# EFR32BG21A020F1024IM32 register map
Vendor: Silicon Labs; Series: EFR32; File version: B
Registers are 32-bit, read-write, reset 0x0 unless marked. A register's access mark holds for its fields unless they carry their own. Offsets are from the block's base; [hi:lo] are bit positions; {n}, {i} and the like mark numbered series; 'fields as' and 'values as' point back to an identical list.

## RAC_S — RAC_S Registers
Base 0xA8020000
Same registers: RAC_NS 0xB8020000
0x00 IPVERSION ro
0x04 EN
  [0] EN — Enable peripheral clock to this module
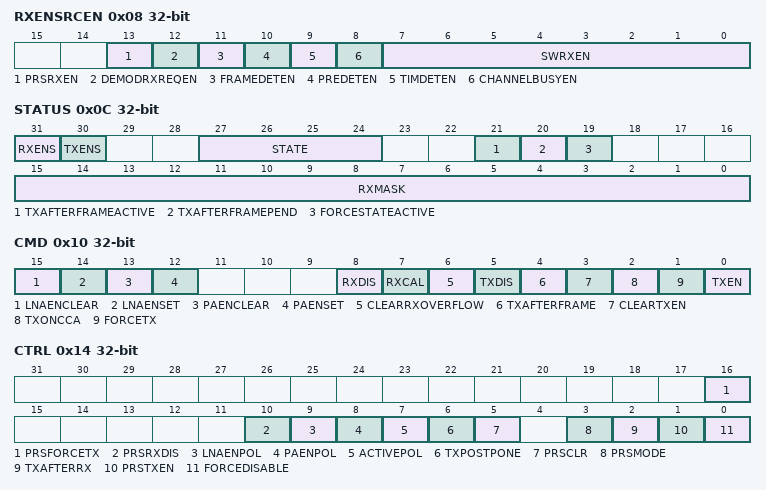
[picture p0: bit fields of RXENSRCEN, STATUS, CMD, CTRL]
0x08 RXENSRCEN
  [13] PRSRXEN — PRS RX Enable
  [12] DEMODRXREQEN — DEMOD RX Request Enable
  [11] FRAMEDETEN — Frame Detected Enable
  [10] PREDETEN — Preamble Detected Enable
  [9] TIMDETEN — Timing Detected Enable
  [8] CHANNELBUSYEN — Channel Busy Enable
  [7:0] SWRXEN — SW RX Enable
0x0C STATUS ro
  [31] RXENS — RXEN Status
    0=RXEN is not set; 1=RXEN is set
  [30] TXENS — TXEN Status
    0=TXEN is not set; 1=TXEN is set
  [27:24] STATE — Radio State
    0=OFF (Radio is off); 1=RXWARM (Radio is enabling receiver); 2=RXSEARCH (Radio is listening for incoming frames); 3=RXFRAME (Radio is receiving a frame); 4=RXPD (Radio is powering down receiver and going to OFF state); 5=RX2RX (Radio remains in receive mode after frame reception is completed); 6=RXOVERFLOW (Received data was lost due to full receive buffer); 7=RX2TX (Radio is disabling receiver and enabling transmitter); 8=TXWARM (Radio is enabling transmitter); 9=TX (Radio is transmitting data); 10=TXPD (Radio is powering down transmitter and going to OFF state); 11=TX2RX (Radio is disabling transmitter and enabling reception); 12=TX2TX (Radio is preparing for a transmission after the previous transmission was ended); 13=SHUTDOWN (Radio is powering down receiver and going to OFF state)
  [21] TXAFTERFRAMEACTIVE
    0=The currently ongoing TX was not initiated by a TXAFTERFRAME command; 1=The currently ongoing TX was initiated by a TXAFTERFRAME command
  [20] TXAFTERFRAMEPEND — TX After Frame Pending
    0=A transmit after frame operation is currently not pending; 1=A transmit after frame operation is currently pending
  [19] FORCESTATEACTIVE — FSM state force active
    0=No special state transition is currently in progress; 1=A forced state transition is currently in progress
  [15:0] RXMASK — Receive Enable Mask
0x10 CMD wo
  [15] LNAENCLEAR
  [14] LNAENSET
  [13] PAENCLEAR
  [12] PAENSET
  [8] RXDIS — RX Disable
  [7] RXCAL — Start an RX Calibration
  [6] CLEARRXOVERFLOW
  [5] TXDIS — TX Disable
  [4] TXAFTERFRAME
  [3] CLEARTXEN — Clear TX Enable
  [2] TXONCCA — Transmit On CCA
  [1] FORCETX — Force TX Command
  [0] TXEN — Transmitter Enable
0x14 CTRL
  [16] PRSFORCETX — PRS Force RX
    0=PRS will not force TX; 1=The channel selected by PRSFORCETXSEL will generate a force TX pulse
  [10] PRSRXDIS — PRS RX Disable
    0=PRS will not disable RX; 1=The channel selected by PRSRXDISSEL will generate a disable RX pulse
  [9] LNAENPOL — LNAEN signal polarity
    0=Active low; 1=Active high
  [8] PAENPOL — PAEN signal polarity
    0=Active low; 1=Active high
  [7] ACTIVEPOL — ACTIVE signal polarity
    0=Active low; 1=Active high
  [6] TXPOSTPONE
    0=In the TX state transmit data is output; 1=In the TX state an unmodulated carrier is output until this bit is cleared
  [5] PRSCLR — PRS RXEN Clear
    0=RXSEARCH (The PRS RXEN signal is cleared when the RSM state enters RXSEARCH); 1=PRSCH (The Selected PRS channel in PRSCLRSEL is used as a disable pulse)
  [3] PRSMODE — PRS RXEN Mode
    0=DIRECT (The PRS signal is used directly); 1=PULSE (The PRS signal is used as an RX enable pulse)
  [2] TXAFTERRX
    0=TX will not be started automatically; 1=A transition to TX is automatically started when a received frame is accepted by the FRC
  [1] PRSTXEN — PRS TX Enable
  [0] FORCEDISABLE — Force Radio Disable
0x18 FORCESTATE
  [3:0] FORCESTATE — Force RAC state transition
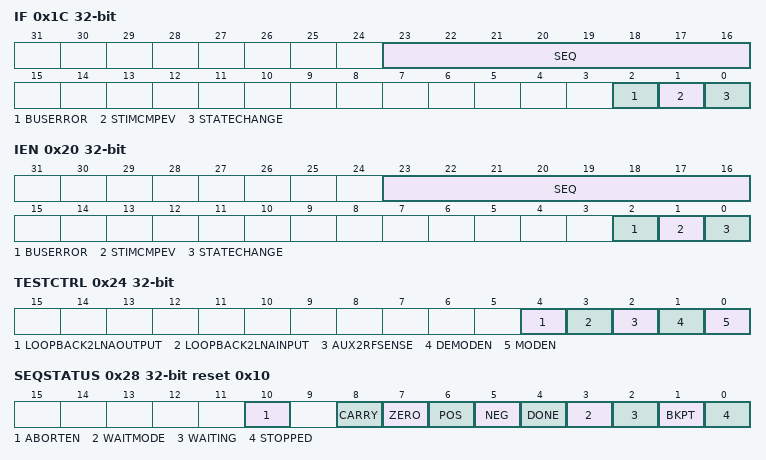
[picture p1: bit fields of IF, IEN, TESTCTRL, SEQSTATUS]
0x1C IF
  [23:16] SEQ — Sequencer Interrupt Flags
  [2] BUSERROR
  [1] STIMCMPEV — STIMER Compare Event
  [0] STATECHANGE — Radio State Change
0x20 IEN
  [23:16] SEQ — Sequencer Flags Interrupt Enable
  [2] BUSERROR — Bus Error Interrupt Enable
  [1] STIMCMPEV — STIMER Compare Event Interrupt Enable
  [0] STATECHANGE — Radio State Change Interrupt Enable
0x24 TESTCTRL
  [4] LOOPBACK2LNAOUTPUT — Enable RF loopback
  [3] LOOPBACK2LNAINPUT — Enable RF loopback
  [2] AUX2RFSENSE — Enable auxiliary synthesizer output
    0=The auxiliary synthesizer is not connected to the RFSENSE input; 1=The auxiliary synthesizer is connected to the RFSENSE input
  [1] DEMODEN — Demodulator enable
  [0] MODEN — Modulator enable
0x28 SEQSTATUS ro reset 0x10
  [10] ABORTEN — Sequencer Program Execution Abort Enable
    0=Sequencer Program Execution can not be aborted; 1=Sequencer Program Execution can be aborted
  [8] CARRY — Carry Flag
  [7] ZERO — Zero Flag
  [6] POS — Positive Flag
  [5] NEG — Negative Flag
  [4] DONE — Sequencer Done Signal
  [3] WAITMODE — Sequencer Waiting Mode
    0=ANY (Sequencer is waiting for any of the events indicated SEQ_WAITMASK.); 1=ALL (Sequencer is waiting for all the events indicated SEQ_WAITMASK.)
  [2] WAITING — Sequencer Waiting
  [1] BKPT — Breakpoint Enabled
  [0] STOPPED — Sequencer Stopped
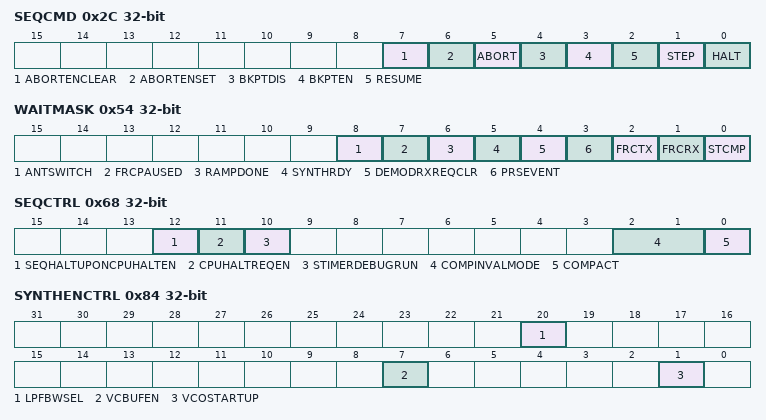
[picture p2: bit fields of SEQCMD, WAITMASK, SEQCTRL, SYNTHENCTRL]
0x2C SEQCMD wo
  [7] ABORTENCLEAR — Clear Sequencer Abort Enable
  [6] ABORTENSET — Set Sequencer Abort Enable
  [5] ABORT — Sequencer Execution Abort
  [4] BKPTDIS — Breakpoint Disable
  [3] BKPTEN — Breakpoint Enable
  [2] RESUME — Sequencer Resume
  [1] STEP — Sequencer Step
  [0] HALT — Sequencer Halt
0x30 BREAKPOINT
  [31:0] BKPADDR — Sequencer Breakpoint Address
{0x34+4i} R{i} (i=0..7)
  [31:0] R{i} — Sequencer Register {i}
0x54 WAITMASK ro
  [8] ANTSWITCH — Active antenna has switched
  [7] FRCPAUSED
  [6] RAMPDONE
  [5] SYNTHRDY — SYNTH Ready
  [4] DEMODRXREQCLR — Demodulator RX Request Clear
  [3] PRSEVENT
  [2] FRCTX — FRC TXWord
  [1] FRCRX — FRC RXWord
  [0] STCMP — STIMER Compare Event
0x58 WAITSNSH ro
  [9:0] WAITSNSH — Wait Event Snapshot
0x5C STIMER ro
  [15:0] STIMER
0x60 STIMERCOMP
  [15:0] STIMERCOMP — STIMER Compare Register
0x64 VECTADDR
  [31:0] VECTADDR — Vector Table Address
0x68 SEQCTRL
  [12] SEQHALTUPONCPUHALTEN — Sequencer Halt Upon CPU Halt Enable
    0=Sequencer is not halted when the main CPU is halted; 1=Sequencer is halted when the main CPU is halted
  [11] CPUHALTREQEN — CPU Halt Request Enable
    0=Main CPU is not halted when the Sequencer is halted; 1=Main CPU is halted when the Sequencer is halted
  [10] STIMERDEBUGRUN
    0=STIMER is not running when the Sequencer is halted; 1=STIMER is running when the Sequencer is halted
  [2:1] COMPINVALMODE — STIMER Comp Invalid Mode
    0=NEVER (STIMERCOMP is always valid); 1=STATECHANGE (STIMERCOMP is invalidated when the RSM changes state); 2=COMPEVENT (STIMERCOMP is invalidated when an STIMER compare event occurs); 3=STATECOMP (STIMERCOMP is invalidated both when the RSM changes state and when a compare event occurs)
  [0] COMPACT — STIMER Compare Action
    0=WRAP (STIMER wraps when reaching STIMERCOMP); 1=CONTINUE (STIMER continues when reaching STIMERCOMP)
0x6C PRESC reset 0x7
  [6:0] STIMER — STIMER Prescaler
{0x70+4i} SR{i} (i=0..3)
  [31:0] SR{i} — Sequencer Storage Register {i}
0x84 SYNTHENCTRL
  [20] LPFBWSEL — LPF bandwidth register selection
    0=LPFBWRX (Select LPFBWRX); 1=LPFBWTX (Select LPFBWTX)
  [7] VCBUFEN — SYLPFVCBUFEN
    0=Disabled; 1=Enabled
  [1] VCOSTARTUP — SYVCOFASTSTARTUP
    0=fast_start_up_0; 1=fast_start_up_1
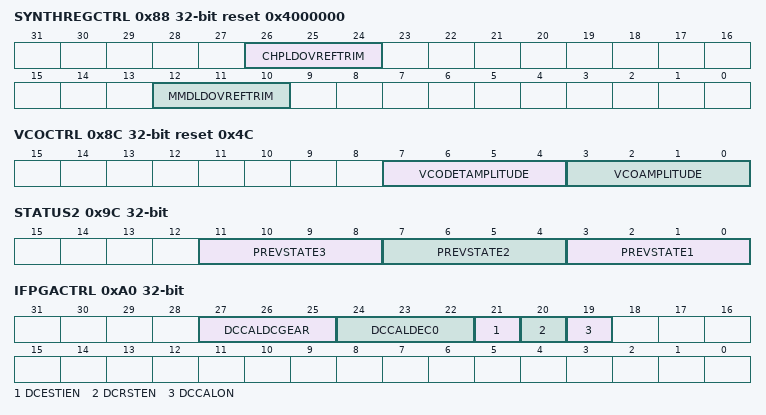
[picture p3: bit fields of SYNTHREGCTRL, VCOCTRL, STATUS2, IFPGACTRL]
0x88 SYNTHREGCTRL reset 0x4000000
  [26:24] CHPLDOVREFTRIM — SYTRIMCHPREGVREF
    0=vref0p6000; 1=vref0p6125; 2=vref0p6250; 3=vref0p6375; 4=vref0p6500; 5=vref0p6625; 6=vref0p6750; 7=vref0p6875
  [12:10] MMDLDOVREFTRIM — SYTRIMMMDREGVREF
    values as CHPLDOVREFTRIM
0x8C VCOCTRL reset 0x4C
  [7:4] VCODETAMPLITUDE — SYVCOAMPLPKD
  [3:0] VCOAMPLITUDE — SYVCOAMPLOPEN
0x94 SYNTHCTRL
  [10] MMDPOWERBALANCEDISABLE — SYMMDPOWERBALANCEENB
    0=EnablePowerbleed; 1=DisablePowerBleed
0x9C STATUS2 ro
  [all] fields
    values as STATUS.STATE
  [11:8] PREVSTATE3 — Previous Radio State 3
  [7:4] PREVSTATE2 — Previous Radio State 2
  [3:0] PREVSTATE1 — Previous Radio State
0xA0 IFPGACTRL
  [27:25] DCCALDCGEAR — DC COMP GEAR Value for DCCAL
  [24:22] DCCALDEC0 — DEC0 Value for DCCAL
    0=DF3 (Decimation Factor 0 = 3. Cutoff 0.050 * f<subscript>HFXO</subscript>.); 1=DF4WIDE (Decimation Factor 0 = 4. Cutoff 0.069 * f<subscript>HFXO</subscript>.); 2=DF4NARROW (Decimation Factor 0 = 4. Cutoff 0.037 * f<subscript>HFXO</subscript>.); 3=DF8WIDE (Decimation Factor 0 = 8. Cutoff 0.012 * f<subscript>HFXO</subscript>.); 4=DF8NARROW (Decimation Factor 0 = 8. Cutoff 0.005 * f<subscript>HFXO</subscript>.)
  [21] DCESTIEN — DCESTIEN Override for RAC
    0=DISABLE (DCESTI Disabled in MODEM); 1=ENABLE (DCESTI Enabled in MODEM)
  [20] DCRSTEN — DC Compensation Filter Reset Enable
    0=DISABLE (DC Comp out of Reset); 1=ENABLE (DC Comp in Reset)
  [19] DCCALON — Enable/Disable DCCAL in DEMOD
    0=DISABLE (DC ESTI DISABLED); 1=ENABLE (DC ESTI ENABLED)
0xA4 PAENCTRL
  [8] PARAMP — PA output level ramping
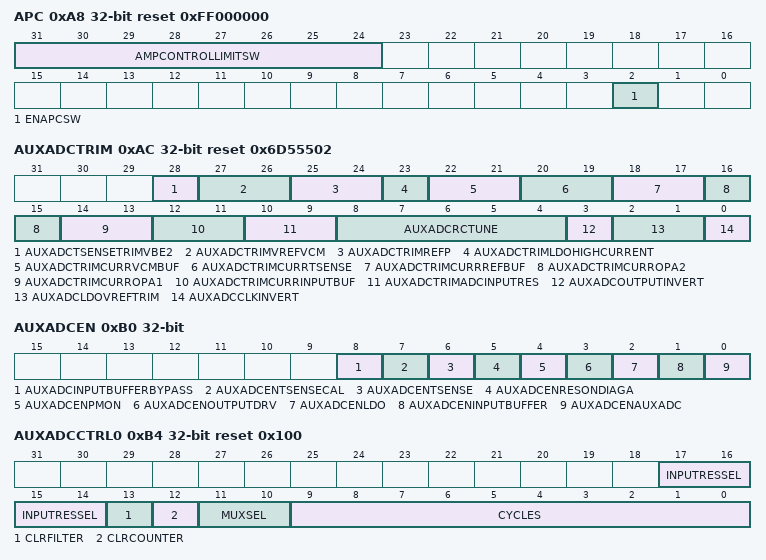
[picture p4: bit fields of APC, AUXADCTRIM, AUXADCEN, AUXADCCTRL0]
0xA8 APC reset 0xFF000000
  [31:24] AMPCONTROLLIMITSW — software amp_control top limit
  [2] ENAPCSW — software control bit for apc
    0=DISABLE; 1=ENABLE
0xAC AUXADCTRIM reset 0x6D55502
  [28] AUXADCTSENSETRIMVBE2
    0=VBE_16uA; 1=VBE_32uA
  [27:26] AUXADCTRIMVREFVCM
    0=Trim0p6; 1=Trim0p65; 2=Trim0p7; 3=Trim0p75
  [25:24] AUXADCTRIMREFP
    0=REF1p05; 1=REF1p16; 2=REF1p2; 3=REF1p25
  [23] AUXADCTRIMLDOHIGHCURRENT
    0=LowCurrentMode; 1=HighCurrentMode
  [22:21] AUXADCTRIMCURRVCMBUF
    0=Typ_minus_40pct; 1=Typ_minus_20pct; 2=Typ; 3=Typ_plus_20pct
  [20:19] AUXADCTRIMCURRTSENSE
    values as AUXADCTRIMCURRVCMBUF
  [18:17] AUXADCTRIMCURRREFBUF
    values as AUXADCTRIMCURRVCMBUF
  [16:15] AUXADCTRIMCURROPA2
    values as AUXADCTRIMCURRVCMBUF
  [14:13] AUXADCTRIMCURROPA1
    values as AUXADCTRIMCURRVCMBUF
  [12:11] AUXADCTRIMCURRINPUTBUF
    values as AUXADCTRIMCURRVCMBUF
  [10:9] AUXADCTRIMADCINPUTRES
    0=RES200k; 1=RES250k; 2=RES300k; 3=RES350k
  [8:4] AUXADCRCTUNE
  [3] AUXADCOUTPUTINVERT
    0=Disabled; 1=Enabled
  [2:1] AUXADCLDOVREFTRIM
    0=TRIM1p27; 1=TRIM1p3; 2=TRIM1p35; 3=TRIM1p4
  [0] AUXADCCLKINVERT
    0=Disable_Invert; 1=Enable_Invert
0xB0 AUXADCEN
  [8] AUXADCINPUTBUFFERBYPASS
    0=Not_Bypassed; 1=Bypassed
  [7] AUXADCENTSENSECAL
    0=Disabled; 1=Enabled
  [6] AUXADCENTSENSE
    0=Disabled; 1=Enabled
  [5] AUXADCENRESONDIAGA
    0=Disabled; 1=Enabled
  [4] AUXADCENPMON
    0=Disabled; 1=Enabled
  [3] AUXADCENOUTPUTDRV
    0=Disabled; 1=Enabled
  [2] AUXADCENLDO
    0=Disabled; 1=Enabled
  [1] AUXADCENINPUTBUFFER
    0=Disabled; 1=Enabled
  [0] AUXADCENAUXADC
    0=Disabled; 1=Enabled
0xB4 AUXADCCTRL0 reset 0x100
  [17:14] INPUTRESSEL — Select input resource
  [13] CLRFILTER — Clear accumulators
  [12] CLRCOUNTER — Clear counter
  [11:10] MUXSEL — Select accumulator
  [9:0] CYCLES — Cycle number to run
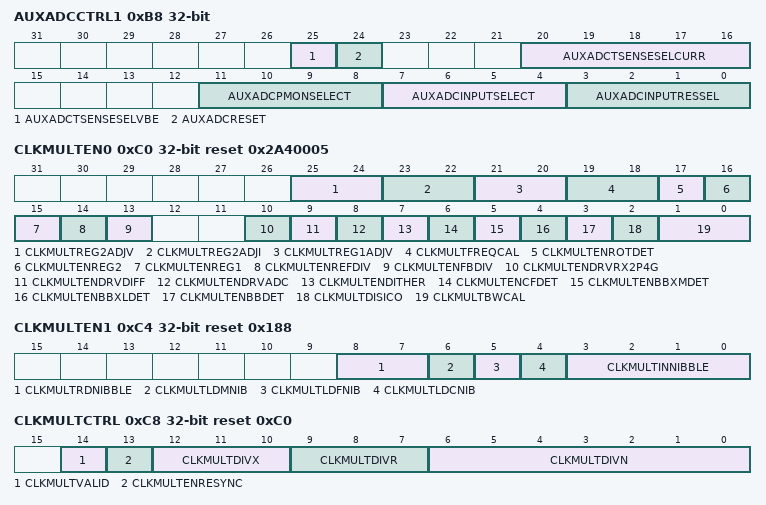
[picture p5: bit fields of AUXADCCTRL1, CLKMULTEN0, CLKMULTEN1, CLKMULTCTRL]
0xB8 AUXADCCTRL1
  [25] AUXADCTSENSESELVBE
    0=VBE1; 1=VBE2
  [24] AUXADCRESET
    0=Reset_Enabled; 1=Reset_Disabled
  [20:16] AUXADCTSENSESELCURR
  [11:8] AUXADCPMONSELECT
  [7:4] AUXADCINPUTSELECT
    {v}=SEL{v} (v=0..9)
  [3:0] AUXADCINPUTRESSEL
    0=RES640kOhm; 1=RES320kOhm; 2=RES160kOhm; 3=RES80kOhm; 4=RES40kOhm; 5=RES20kOhm; 6=RES10kOhm; 7=RES5kOhm; 8=RES2p5kOhm; 9=RES1p25kOhm; 10=RES0p6kOhm; 11=RES_switch
0xBC AUXADCOUT ro
  [27:0] AUXADCOUT — AUXADC output
0xC0 CLKMULTEN0 reset 0x2A40005
  [25:24] CLKMULTREG2ADJV
    0=v1p03; 1=v1p09; 2=v1p10; 3=v1p16
  [23:22] CLKMULTREG2ADJI
    0=I_200uA; 1=I_480uA; 2=I_760uA; 3=I_1040uA
  [21:20] CLKMULTREG1ADJV
    0=v1p28; 1=v1p32; 2=v1p33; 3=v1p38
  [19:18] CLKMULTFREQCAL
    0=pedes_14uA; 1=pedes_22uA; 2=pedes_30uA; 3=pedes_38uA
  [17] CLKMULTENROTDET
    0=disable; 1=enable
  [16] CLKMULTENREG2
    0=disable; 1=enable
  [15] CLKMULTENREG1
    0=disable; 1=enable
  [14] CLKMULTENREFDIV
    0=disable; 1=enable
  [13] CLKMULTENFBDIV
    0=disable; 1=enable
  [10] CLKMULTENDRVRX2P4G
    0=disable; 1=enable
  [9] CLKMULTENDRVDIFF
    0=Single_ended; 1=Differential
  [8] CLKMULTENDRVADC
    0=disable; 1=enable
  [7] CLKMULTENDITHER
    0=disable; 1=enable
  [6] CLKMULTENCFDET
    0=disable; 1=enable
  [5] CLKMULTENBBXMDET
    0=disable; 1=enable
  [4] CLKMULTENBBXLDET
    0=disable; 1=enable
  [3] CLKMULTENBBDET
    0=disable; 1=enable
  [2] CLKMULTDISICO
    0=enable; 1=disable
  [1:0] CLKMULTBWCAL
    {v}=bw_{v+1}lsb (v=0..3)
0xC4 CLKMULTEN1 reset 0x188
  [8:7] CLKMULTRDNIBBLE
    0=quarter_nibble; 1=fine_nibble; 2=moderate_nibble; 3=coarse_nibble
  [6] CLKMULTLDMNIB
    0=disable; 1=enable
  [5] CLKMULTLDFNIB
    0=disable; 1=enable
  [4] CLKMULTLDCNIB
    0=disable; 1=enable
  [3:0] CLKMULTINNIBBLE
0xC8 CLKMULTCTRL reset 0xC0
  [14] CLKMULTVALID
    0=invalid; 1=valid
  [13] CLKMULTENRESYNC
    0=disable_sync; 1=enable_sync
  [12:10] CLKMULTDIVX
    0=div_1; 1=div_2; 2=div_4; 3=div_6; 4=div_8; 5=div10; 6=div12; 7=div14
  [9:7] CLKMULTDIVR
  [6:0] CLKMULTDIVN
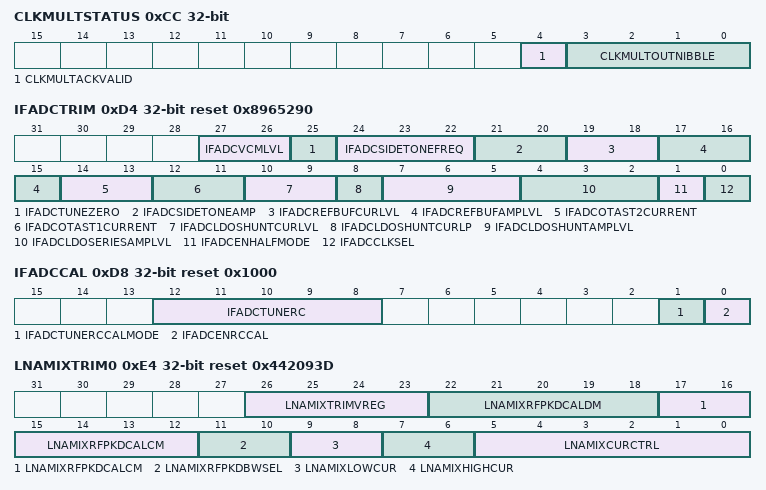
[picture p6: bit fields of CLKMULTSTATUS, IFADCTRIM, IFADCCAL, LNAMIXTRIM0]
0xCC CLKMULTSTATUS ro
  [4] CLKMULTACKVALID
    0=invalid; 1=valid
  [3:0] CLKMULTOUTNIBBLE
0xD4 IFADCTRIM reset 0x8965290
  [27:26] IFADCVCMLVL
    0=ratio_0p48; 1=ratio_0p49; 2=ratio_0p5; 3=ratio_0p52
  [25] IFADCTUNEZERO
    0=nominal_zero; 1=half_freq_zero
  [24:22] IFADCSIDETONEFREQ
    0=na0; 1=div_128; 2=div_64; 3=div_32; 4=div_16; 5=div_8; 6=div_4; 7=na7
  [21:20] IFADCSIDETONEAMP
    0=diff_pk_10mV; 1=diff_pk_20mV; 2=diff_pk_50mV; 3=diff_pk_100mV
  [19:18] IFADCREFBUFCURLVL
    0=current_65uA; 1=current_75uA; 2=current_85uA; 3=current_95uA
  [17:15] IFADCREFBUFAMPLVL
    0=v0p88; 1=v0p91; 2=v0p94; 3=v0p97; 4=v1p00; 5=v1p03; 6=v1p06; 7=v1p09
  [14:13] IFADCOTAST2CURRENT
    0=negative_20p; 1=negative_11p; 2=nominal; 3=positive_15p
  [12:11] IFADCOTAST1CURRENT
    0=negative_20p; 1=negative_11p; 2=nominal; 3=positive_15p
  [10:9] IFADCLDOSHUNTCURLVL
    0=current_180uA; 1=current_190uA; 2=current_200uA; 3=current_210uA
  [8] IFADCLDOSHUNTCURLP
    0=low_power_disabled; 1=low_power_enabled
  [7:5] IFADCLDOSHUNTAMPLVL
    0=v1p20; 1=v1p24; 2=v1p28; 3=v1p32; 4=v1p35; 5=v1p39; 6=v1p42; 7=v1p46
  [4:2] IFADCLDOSERIESAMPLVL
    values as IFADCLDOSHUNTAMPLVL
  [1] IFADCENHALFMODE
    0=full_speed_mode; 1=half_speed_mode
  [0] IFADCCLKSEL
    0=clk_2p4g; 1=clk_subg
0xD8 IFADCCAL reset 0x1000
  [12:8] IFADCTUNERC
  [1] IFADCTUNERCCALMODE
    0=SYmode; 1=ADCmode
  [0] IFADCENRCCAL
    0=rccal_disable; 1=rccal_enable
0xDC IFADCSTATUS ro
  [0] IFADCRCCALOUT
    0=lo; 1=hi
0xE4 LNAMIXTRIM0 reset 0x442093D
  [26:23] LNAMIXTRIMVREG
  [22:18] LNAMIXRFPKDCALDM
  [17:12] LNAMIXRFPKDCALCM
  [11:10] LNAMIXRFPKDBWSEL
  [9:8] LNAMIXLOWCUR
    0=current_nom; 2=current_80percent; 3=current_60percent
  [7:6] LNAMIXHIGHCUR
    0=current_470uA; 1=current_530uA; 3=current_590uA
  [5:0] LNAMIXCURCTRL
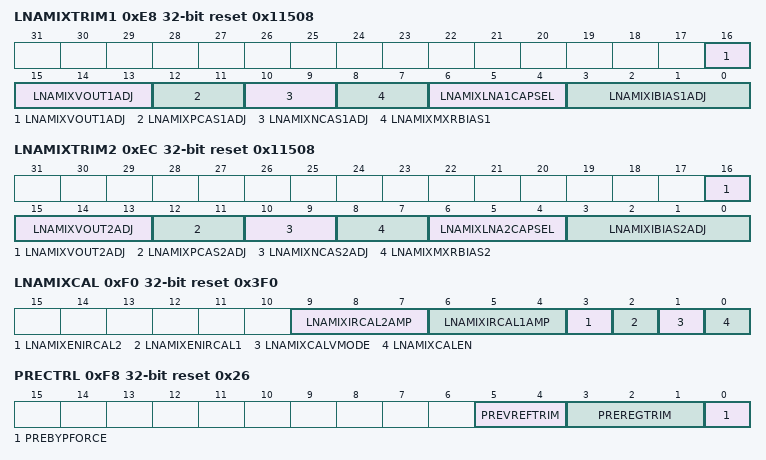
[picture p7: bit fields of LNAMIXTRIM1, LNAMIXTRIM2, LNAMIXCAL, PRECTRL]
0xE8 LNAMIXTRIM1 reset 0x11508
  [16:13] LNAMIXVOUT1ADJ
  [12:11] LNAMIXPCAS1ADJ
    0=pcas_250m; 2=pcas_300m; 3=pcas_350m
  [10:9] LNAMIXNCAS1ADJ
    0=ncas_1V; 2=ncas_950m; 3=ncas_900m
  [8:7] LNAMIXMXRBIAS1
    0=bias_1V; 2=bias_900m; 3=bias_800m
  [6:4] LNAMIXLNA1CAPSEL
  [3:0] LNAMIXIBIAS1ADJ
0xEC LNAMIXTRIM2 reset 0x11508
  [16:13] LNAMIXVOUT2ADJ
  [12:11] LNAMIXPCAS2ADJ
    0=pcas_250m; 2=pcas_300m; 3=pcas_350m
  [10:9] LNAMIXNCAS2ADJ
    0=ncas_1V; 2=ncas_950m; 3=ncas_900m
  [8:7] LNAMIXMXRBIAS2
    0=bias_1V; 2=bias_900m; 3=bias_800m
  [6:4] LNAMIXLNA2CAPSEL
  [3:0] LNAMIXIBIAS2ADJ
0xF0 LNAMIXCAL reset 0x3F0
  [9:7] LNAMIXIRCAL2AMP
  [6:4] LNAMIXIRCAL1AMP
  [3] LNAMIXENIRCAL2
    0=disable; 1=enable
  [2] LNAMIXENIRCAL1
    0=disable; 1=enable
  [1] LNAMIXCALVMODE
    0=current_mode; 1=voltage_mode
  [0] LNAMIXCALEN
    0=cal_disable; 1=cal_enable
0xF4 LNAMIXEN
  [0] LNAMIXENLDO
    0=disable; 1=enable
0xF8 PRECTRL reset 0x26
  [5:4] PREVREFTRIM
    0=v0p675; 1=v0p688; 2=v0p700; 3=v0p713
  [3:1] PREREGTRIM
    0=v1p61; 1=v1p68; 2=v1p74; 3=v1p80; 4=v1p86; 5=v1p91; 6=v1p96; 7=v2p00
  [0] PREBYPFORCE
    0=not_forced; 1=forced
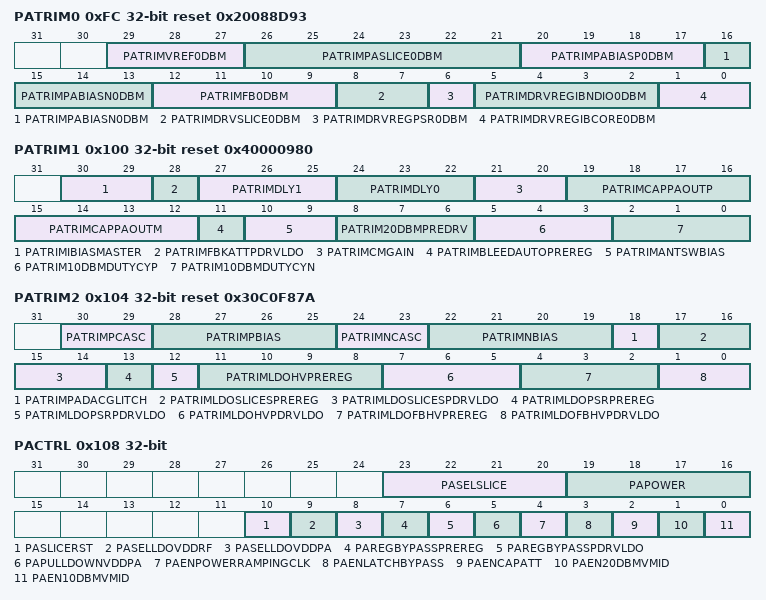
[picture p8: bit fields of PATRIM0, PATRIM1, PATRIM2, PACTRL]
0xFC PATRIM0 reset 0x20088D93
  [29:27] PATRIMVREF0DBM
    0=v_900m; 1=v_912p5m; 2=v_925m; 3=v_937p5m; 4=v_950m; 5=v_962p5m; 6=v_975m; 7=v_987p5m
  [26:21] PATRIMPASLICE0DBM
    0=on_slice_0; 63=on_slice_63
  [20:17] PATRIMPABIASP0DBM
    0=v_450m; 1=v_462p5m; 2=v_475m; 3=v_487p5m; 4=v_500m; 5=v_512p5m; 6=v_525m; 7=v_537p5m; 8=v_550m; 9=v_562p5m; 10=v_575m; 11=v_587p5m; 12=v_600m; 13=v_612p5m; 14=v_625m; 15=v_637p5m
  [16:13] PATRIMPABIASN0DBM
    values as PATRIMPABIASP0DBM
  [12:9] PATRIMFB0DBM
    0=vo_vi_0p475; 1=vo_vi_0p500; 2=vo_vi_0p525; 3=vo_vi_0p550; 4=vo_vi_0p575; 5=vo_vi_0p600; 6=vo_vi_0p625; 7=vo_vi_0p650; 8=vo_vi_0p675; 9=vo_vi_0p700; 10=vo_vi_0p725; 11=vo_vi_0p750; 12=vo_vi_0p775; 13=vo_vi_0p80; 14=vo_vi_0p825; 15=vo_vi_0p85
  [8:7] PATRIMDRVSLICE0DBM
    {v}=on_{v}_slice (v=0..3)
  [6] PATRIMDRVREGPSR0DBM
    0=disable; 1=enable
  [5:2] PATRIMDRVREGIBNDIO0DBM
    0=vreg_1p09; 1=vreg_1p13; 2=vreg_1p16; 3=vreg_1p20; 4=vreg_1p23; 5=vreg_1p25; 6=vreg_1p28; 7=vreg_1p31; 8=vreg_1p33; 9=vreg_1p36; {v}=NA_{v} (v=10..15)
  [1:0] PATRIMDRVREGIBCORE0DBM
    {v}=i_{v+4}u (v=0..3)
0x100 PATRIM1 reset 0x40000980
  [30:29] PATRIMIBIASMASTER
    0=Ibias_is_45u; 1=Ibias_is_47p5u; 2=Ibias_is_50u; 3=Ibias_is_52p5u
  [28] PATRIMFBKATTPDRVLDO
    0=less_bw; 1=more_bw
  [27:25] PATRIMDLY1
    0=tdly_0ps; 1=tdly_64ps; 2=tdly_65ps; 3=tdly_66ps; 4=tdly_68ps; 5=tdly_70ps; 6=tdly_75ps; 7=tdly_83ps
  [24:22] PATRIMDLY0
    values as PATRIMDLY1
  [21:20] PATRIMCMGAIN
  [19:16] PATRIMCAPPAOUTP
  [15:12] PATRIMCAPPAOUTM
  [11] PATRIMBLEEDAUTOPREREG
    0=not_automatic; 1=automatic
  [10:9] PATRIMANTSWBIAS
    0=vb_at_vdd; 1=vb_at_vdd_mp6v; 2=vb_at_vdd_m1p2v; 3=vb_at_vdd_m1p8v
  [8:6] PATRIM20DBMPREDRV
    0=trise_137ps; 1=trise_127ps; 2=trise_117ps; 3=trise_110ps; 4=trise_75ps; 5=trise_73ps; 6=trise_71ps; 7=trise_70ps
  [5:3] PATRIM10DBMDUTYCYP
    {v}=dn_{v}pct (v=0..6); 7=na
  [2:0] PATRIM10DBMDUTYCYN
    {v}=up_{v}pct (v=0..6); 7=na
0x104 PATRIM2 reset 0x30C0F87A
  [30:29] PATRIMPCASC
    0=pcbias_p50mv; 1=pcbias_default; 2=pcbias_m50mv; 3=pcbias_m100mv
  [28:25] PATRIMPBIAS
    0=vpbias_up104mv; 1=vpbias_up91mv; 2=vpbias_up78mv; 3=vpbias_up65mv; 4=vpbias_up52mv; 5=vpbias_up39mv; 6=vpbias_up26mv; 7=vpbias_up13mv; 8=vpbias_default; 9=vpbias_dn13mv; 10=vpbias_dn26mv; 11=vpbias_dn38mv; 12=vpbias_dn52mv; 13=vpbias_dn65mv; 14=vpbias_dn78mv; 15=vpbias_dn91mv
  [24:23] PATRIMNCASC
    0=ncbias_m50mv; 1=ncbias_default; 2=ncbias_p50mv; 3=ncbias_p100mv
  [22:19] PATRIMNBIAS
    0=vnbias_dn104mv; 1=vnbias_dn91mv; 2=vnbias_dn78mv; 3=vnbias_dn65mv; 4=vnbias_dn52mv; 5=vnbias_dn39mv; 6=vnbias_dn26mv; 7=vnbias_dn13mv; 8=vnbias_default; 9=vnbias_up13mv; 10=vnbias_up26mv; 11=vnbias_up39mv; 12=vnbias_up52mv; 13=vnbias_up65mv; 14=vnbias_up78mv; 15=vnbias_up91mv
  [18] PATRIMPADACGLITCH
    0=larger_glitch; 1=smaller_glitch
  [17:16] PATRIMLDOSLICESPREREG
    {v}=spare{v+1} (v=0..3)
  [15:14] PATRIMLDOSLICESPDRVLDO
    0=iload_7p5mA; 1=iload_15mA; 2=iload_22p5mA; 3=iload_30mA
  [13] PATRIMLDOPSRPREREG
    0=low_psr; 1=high_psr
  [12] PATRIMLDOPSRPDRVLDO
    0=low_psr; 1=high_psr
  [11:8] PATRIMLDOHVPREREG
    0=vref_0p651; 1=vref_0p663; 2=vref_0p676; 3=vref_0p688; 4=vref_0p701; 5=vref_0p713; 6=vref_0p726; 7=vref_0p738; 8=vref_0p751; 9=vref_0p763; 10=vref_0p776; 11=vref_0p788; 12=vref_0p801; 13=vref_0p813; 14=vref_0p826; 15=vref_0p838
  [7:5] PATRIMLDOHVPDRVLDO
    0=vref_0p675; 1=vref_0p700; 2=vref_0p725; 3=vref_0p750; 4=vref_0p775; 5=vref_0p800; 6=vref_0p825; 7=vref_0p850
  [4:2] PATRIMLDOFBHVPREREG
    0=vreg_1p678; 1=vreg_1p735; 2=vreg_1p801; 3=vreg_1p875; 4=vreg_3p00; 5=vreg_3p14; 6=vreg_3p3; 7=vreg_3p477
  [1:0] PATRIMLDOFBHVPDRVLDO
    0=vreg_1p22; 1=vreg_1p28; 2=vreg_1p35; 3=vreg_1p44
0x108 PACTRL
  [23:20] PASELSLICE
  [19:16] PAPOWER
    {v}=t{v}stripeon (v=0..15)
  [10] PASLICERST
    0=disable; 1=enable
  [9] PASELLDOVDDRF
    0=not_selected; 1=selected
  [8] PASELLDOVDDPA
    0=not_selected; 1=selected
  [7] PAREGBYPASSPREREG
    0=not_bypass; 1=bypass
  [6] PAREGBYPASSPDRVLDO
    0=not_bypass; 1=bypass
  [5] PAPULLDOWNVDDPA
    0=not_pull_down; 1=pull_down_vddpa
  [4] PAENPOWERRAMPINGCLK
    0=silence_clk; 1=en_clk
  [3] PAENLATCHBYPASS
    0=disable; 1=enable
  [2] PAENCAPATT
    0=disable; 1=enable
  [1] PAEN20DBMVMID
    0=disable; 1=enable
  [0] PAEN10DBMVMID
    0=disable; 1=enable
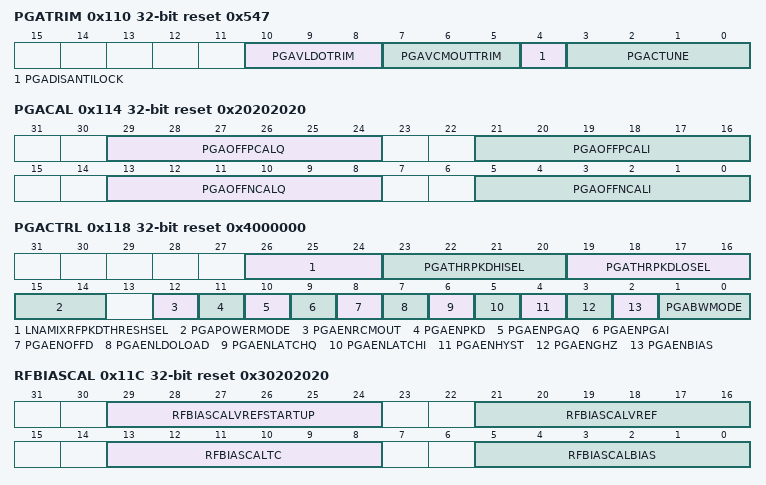
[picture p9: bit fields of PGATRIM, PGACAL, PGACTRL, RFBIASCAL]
0x110 PGATRIM reset 0x547
  [10:8] PGAVLDOTRIM
    0=vdda_1p15; 1=vdda_1p2; 2=vdda_1p25; 3=vdda_1p3; 4=vdda_1p35; 5=vdda_1p4; 6=vdda_1p5; 7=vdda_1p55
  [7:5] PGAVCMOUTTRIM
    0=vcm_out_0p4; 1=vcm_out_0p45; 2=vcm_out_0p5; 3=vcm_out_0p55; 4=vcm_out_0p6; 5=vcm_out_0p65; 6=vcm_out_0p7; 7=vcm_out_0p75
  [4] PGADISANTILOCK
    0=antilock_enable; 1=antilock_disable
  [3:0] PGACTUNE
    0=cfb_0p7; 7=cfb_nominal; 15=cfb_1p32
0x114 PGACAL reset 0x20202020
  [all] fields
    0=offset_m_300mv; 63=offset_p_300mv
  [29:24] PGAOFFPCALQ
  [21:16] PGAOFFPCALI
  [13:8] PGAOFFNCALQ
  [5:0] PGAOFFNCALI
0x118 PGACTRL reset 0x4000000
  [26:24] LNAMIXRFPKDTHRESHSEL
  [23:20] PGATHRPKDHISEL
    0=vref50mv; 1=vref75mv; 2=vref100mv; 3=vref125mv; 4=verf150mv; 5=vref175mv; 6=vref200mv; 7=vref225mv; 8=vref250mv; 9=vref275mv; 10=vref300mv
  [19:16] PGATHRPKDLOSEL
    0=vref50mv; 1=vref75mv; 2=vref100mv; 3=vref125mv; 4=vref150mv; 5=vref175mv; 6=vref200mv; 7=vref225mv; 8=vref250mv; 9=vref275mv; 10=vref300mv
  [15:14] PGAPOWERMODE
    0=pm_typ; 1=pm_0p8; 2=pm_1p2; 3=pm_0p5
  [12] PGAENRCMOUT
    0=rcm_out_disable; 1=rcm_out_enable
  [11] PGAENPKD
    0=pkd_disable; 1=pkd_enable
  [10] PGAENPGAQ
    0=pgaq_disable; 1=pgaq_enable
  [9] PGAENPGAI
    0=pgai_disable; 1=pgai_enable
  [8] PGAENOFFD
    0=pkd_offd_disable; 1=pkd_offd_enable
  [7] PGAENLDOLOAD
    0=disable_ldo_load; 1=enable_ldo_load
  [6] PGAENLATCHQ
    0=pkd_latch_q_disable; 1=pkd_latch_q_enable
  [5] PGAENLATCHI
    0=pkd_latch_i_disable; 1=pkd_latch_i_enable
  [4] PGAENHYST
    0=pkd_hyst_disable; 1=pkd_hyst_enable
  [3] PGAENGHZ
    0=ghz_disable; 1=ghz_enable
  [2] PGAENBIAS
    0=bias_disable; 1=bias_enable
  [1:0] PGABWMODE
    0=bw_5MHz; 1=bw_2p5MHz; 2=bw_1p67MHz; 3=bw_1p25MHz
0x11C RFBIASCAL reset 0x30202020
  [29:24] RFBIASCALVREFSTARTUP, [21:16] RFBIASCALVREF, [13:8] RFBIASCALTC, [5:0] RFBIASCALBIAS
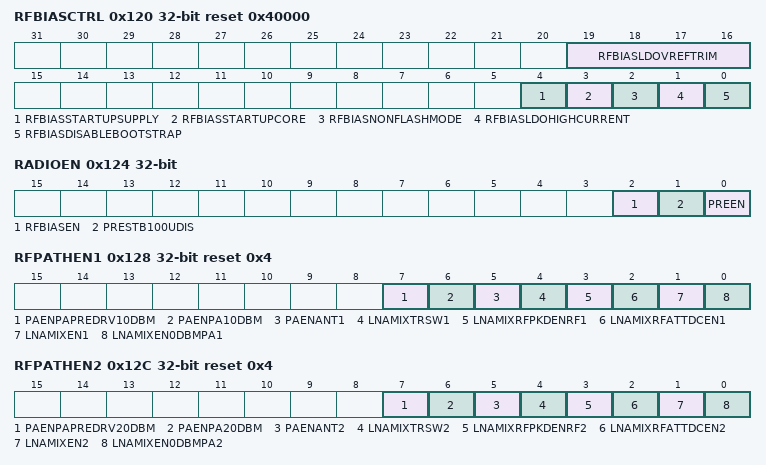
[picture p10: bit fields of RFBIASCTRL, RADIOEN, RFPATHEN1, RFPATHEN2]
0x120 RFBIASCTRL reset 0x40000
  [19:16] RFBIASLDOVREFTRIM
    0=vref_v0p800; 1=vref_v0p813; 2=vref_v0p825; 3=vref_v0p837; 4=vref_v0p850; 5=vref_v0p863; 6=vref_v0p875; 7=vref_v0p887; 8=vref_v0p900; 9=vref_v0p913; 10=vref_v0p925; 11=vref_v0p938; 12=vref_v0p950; 13=vref_v0p963; 14=vref_v0p975; 15=vref_v0p988
  [4] RFBIASSTARTUPSUPPLY
    0=default; 1=forc_start
  [3] RFBIASSTARTUPCORE
    0=default; 1=force_start
  [2] RFBIASNONFLASHMODE
    0=flash_process; 1=non_flash_process
  [1] RFBIASLDOHIGHCURRENT
    0=low_current; 1=high_current
  [0] RFBIASDISABLEBOOTSTRAP
    0=enable_startup; 1=disable_startup
0x124 RADIOEN
  [2] RFBIASEN
    0=disable_dualbis_vtr; 1=enable_dualbis_vtr
  [1] PRESTB100UDIS
    0=i100ua_enabled; 1=i100ua_disabled
  [0] PREEN
    0=powered_off; 1=powered_on
0x128 RFPATHEN1 reset 0x4
  [7] PAENPAPREDRV10DBM
    0=disable; 1=enable
  [6] PAENPA10DBM
    0=disable; 1=enable
  [5] PAENANT1
    0=disable; 1=enable
  [4] LNAMIXTRSW1
    0=disabled; 1=enabled
  [3] LNAMIXRFPKDENRF1
    0=disable; 1=enable_path1
  [2] LNAMIXRFATTDCEN1
    0=disable_dc; 1=enable_dc
  [1] LNAMIXEN1
    0=disable; 1=enable
  [0] LNAMIXEN0DBMPA1
    0=disable; 1=enable
0x12C RFPATHEN2 reset 0x4
  [7] PAENPAPREDRV20DBM
    0=disable; 1=enable
  [6] PAENPA20DBM
    0=disable; 1=enable
  [5] PAENANT2
    0=disable; 1=enable
  [4] LNAMIXTRSW2
    0=disable; 1=enable
  [3] LNAMIXRFPKDENRF2
    0=disable; 1=enable_path2
  [2] LNAMIXRFATTDCEN2
    0=disable; 1=enable
  [1] LNAMIXEN2
    0=disable; 1=enable
  [0] LNAMIXEN0DBMPA2
    0=disable; 1=enable
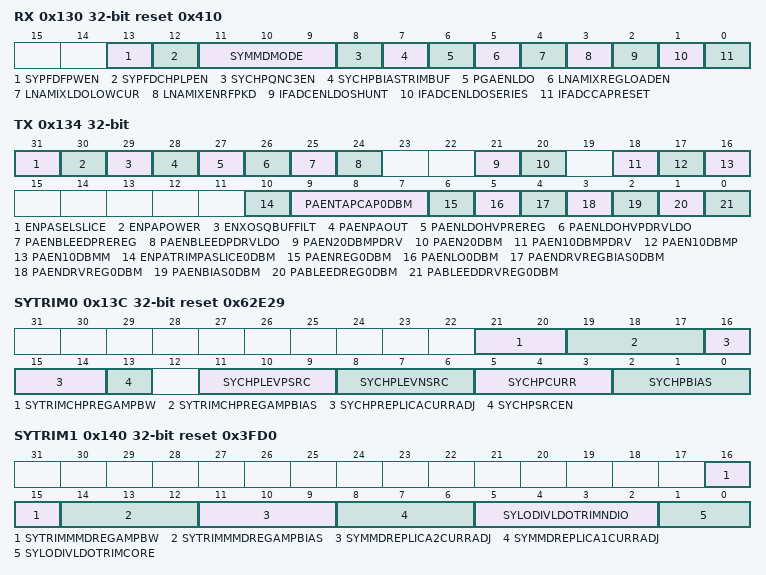
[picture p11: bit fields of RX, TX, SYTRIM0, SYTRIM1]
0x130 RX reset 0x410
  [13] SYPFDFPWEN
    0=disable; 1=enable
  [12] SYPFDCHPLPEN
    0=disable; 1=enable
  [11:9] SYMMDMODE
    0=rx_w_swctrl; 1=rx_wo_swctrl; 2=qnc_dsm2; 3=qnc_dsm3; 4=rxlp_wo_swctrl; 5=notuse_5; 6=notuse_6; 7=notuse_7
  [8] SYCHPQNC3EN
    0=qnc_2; 1=qnc_3
  [7] SYCHPBIASTRIMBUF
    0=i_tail_10u; 1=i_tail_20u
  [6] PGAENLDO
    0=disable_ldo; 1=enable_ldo
  [5] LNAMIXREGLOADEN
    0=disable_resistor; 1=enable_resistor
  [4] LNAMIXLDOLOWCUR
    0=regular_mode; 1=low_current_mode
  [3] LNAMIXENRFPKD
    0=disable; 1=enable
  [2] IFADCENLDOSHUNT
    0=shunt_ldo_disable; 1=shunt_ldo_enable
  [1] IFADCENLDOSERIES
    0=series_ldo_disable; 1=series_ldo_enable
  [0] IFADCCAPRESET
    0=cap_reset_disable; 1=cap_reset_enable
0x134 TX
  [31] ENPASELSLICE — Override
  [30] ENPAPOWER — Override
  [29] ENXOSQBUFFILT — Override
  [28] PAENPAOUT
    0=disable; 1=enable
  [27] PAENLDOHVPREREG
    0=disable; 1=enable
  [26] PAENLDOHVPDRVLDO
    0=disable; 1=enable
  [25] PAENBLEEDPREREG
    0=disable; 1=enable
  [24] PAENBLEEDPDRVLDO
    0=disable; 1=enable
  [21] PAEN20DBMPDRV
    0=disable; 1=enable
  [20] PAEN20DBM
    0=disable; 1=enable
  [18] PAEN10DBMPDRV
    0=disable; 1=enable
  [17] PAEN10DBMP
    0=disable; 1=enable
  [16] PAEN10DBMM
    0=disable; 1=enable
  [10] ENPATRIMPASLICE0DBM — Override
  [9:7] PAENTAPCAP0DBM
    0=cap_0f; 1=cap_0p35pF; 2=cap_0p7pF; 3=cap_1p05pF; 4=cap_1p4pF; 5=cap_1p75pF; 6=cap_2p1pF; 7=cap_2p45pF
  [6] PAENREG0DBM
    0=disable; 1=enable
  [5] PAENLO0DBM
    0=disable; 1=enable
  [4] PAENDRVREGBIAS0DBM
    0=disable; 1=enable
  [3] PAENDRVREG0DBM
    0=disable; 1=enable
  [2] PAENBIAS0DBM
    0=disable; 1=enable
  [1] PABLEEDREG0DBM
    0=disable; 1=enable
  [0] PABLEEDDRVREG0DBM
    0=disable; 1=enable
0x13C SYTRIM0 reset 0x62E29
  [21:20] SYTRIMCHPREGAMPBW
    0=C_000f; 1=C_300f; 2=C_600f; 3=C_900f
  [19:17] SYTRIMCHPREGAMPBIAS
    0=bias_14uA; 1=bias_20uA; 2=bias_26uA; 3=bias_32uA; 4=bias_38uA; 5=bias_44uA; 6=bias_50uA; 7=bias_56uA
  [16:14] SYCHPREPLICACURRADJ
    0=load_8ua; 1=load_16ua; 2=load_20ua; 3=load_28ua; 4=load_24ua; 5=load_32ua; 6=load_36ua; 7=load_44ua
  [13] SYCHPSRCEN
    0=disable; 1=enable
  [11:9] SYCHPLEVPSRC
    0=vsrcp_n105m; 1=vsrcp_n90m; 2=vsrcp_n75m; 3=vsrcp_n60m; 4=vsrcp_n45m; 5=vsrcp_n30m; 6=vsrcp_n15m; 7=vsrcp_n0m
  [8:6] SYCHPLEVNSRC
  [5:3] SYCHPCURR
    0=curr_1p5uA; 1=curr_2p0uA; 2=curr_2p5uA; 3=curr_3p0uA; 4=curr_3p5uA; 5=curr_4p0uA; 6=curr_4p5uA; 7=curr_5p0uA
  [2:0] SYCHPBIAS
    0=bias_0; 1=bias_1; 3=bias_2; 7=bias_3
0x140 SYTRIM1 reset 0x3FD0
  [16:15] SYTRIMMMDREGAMPBW
    0=C_000f; 1=C_300f; 2=C_600f; 3=C_900f
  [14:12] SYTRIMMMDREGAMPBIAS
    values as SYTRIM0.SYTRIMCHPREGAMPBIAS
  [11:9] SYMMDREPLICA2CURRADJ
    0=load_32u; 1=load_64u; 2=load_96u; 3=load_128u; 4=load_160u; 5=load_192u; 6=load_224u; 7=load_256u
  [8:6] SYMMDREPLICA1CURRADJ
    0=load_8ua; 1=load_16u; 2=load_20ua; 3=load_28ua; 4=load_24ua; 5=load_32ua; 6=load_36ua; 7=load_44ua
  [5:2] SYLODIVLDOTRIMNDIO
    0=vreg_1p08; 1=vreg_1p11; 2=vreg_1p15; 3=vreg_1p18; 4=vreg_1p21; 5=vreg_1p24; 6=vreg_1p27; 7=vreg_1p29; 8=vreg_1p32; 9=vreg_1p34
  [1:0] SYLODIVLDOTRIMCORE
    0=RXLO; 3=TXLO
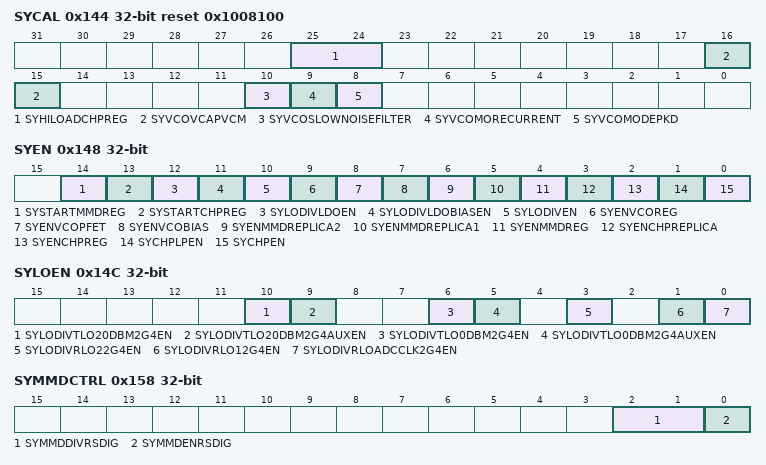
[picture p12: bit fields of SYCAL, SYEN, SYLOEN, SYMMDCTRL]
0x144 SYCAL reset 0x1008100
  [25:24] SYHILOADCHPREG
    0=i_350uA; 1=i_500uA; 2=i_550uA; 3=i_700uA
  [16:15] SYVCOVCAPVCM
  [10] SYVCOSLOWNOISEFILTER
    0=slow_noise_filter_0; 1=slow_noise_filter_1
  [9] SYVCOMORECURRENT
    0=more_current_0; 1=more_current_1
  [8] SYVCOMODEPKD
    0=t_openloop_0; 1=t_pkdetect_1
0x148 SYEN
  [14] SYSTARTMMDREG
    0=no_fast_startup; 1=fast_startup
  [13] SYSTARTCHPREG
    0=no_fast_startup; 1=fast_startup
  [12] SYLODIVLDOEN
    0=disable; 1=enable
  [11] SYLODIVLDOBIASEN
    0=disable; 1=enable
  [10] SYLODIVEN
    0=disable; 1=enable
  [9] SYENVCOREG
    0=en_vco_reg_0; 1=en_vco_reg_1
  [8] SYENVCOPFET
    0=en_vco_pfet_0; 1=en_vco_pfet_1
  [7] SYENVCOBIAS
    0=en_vco_bias_0; 1=en_vco_bias_1
  [6] SYENMMDREPLICA2
    0=Disable; 1=Enable
  [5] SYENMMDREPLICA1
    0=disable; 1=enable
  [4] SYENMMDREG
    0=Disable; 1=Enable
  [3] SYENCHPREPLICA
    0=disable; 1=enable
  [2] SYENCHPREG
    0=Disable; 1=Enable
  [1] SYCHPLPEN
    0=disable; 1=enable
  [0] SYCHPEN
    0=disable; 1=enable
0x14C SYLOEN
  [all] fields
    0=disable; 1=enable
  [10] SYLODIVTLO20DBM2G4EN
  [9] SYLODIVTLO20DBM2G4AUXEN
  [6] SYLODIVTLO0DBM2G4EN
  [5] SYLODIVTLO0DBM2G4AUXEN
  [3] SYLODIVRLO22G4EN
  [1] SYLODIVRLO12G4EN
  [0] SYLODIVRLOADCCLK2G4EN
0x158 SYMMDCTRL
  [2:1] SYMMDDIVRSDIG
    0=Divideby1; 1=Divideby2; 2=Divideby4; 3=Divideby8
  [0] SYMMDENRSDIG
    0=disable; 1=enable
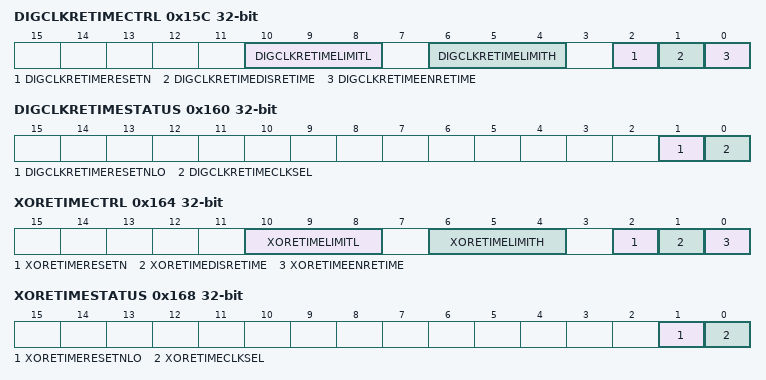
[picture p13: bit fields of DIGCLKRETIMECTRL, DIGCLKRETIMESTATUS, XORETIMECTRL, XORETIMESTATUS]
0x15C DIGCLKRETIMECTRL
  [10:8] DIGCLKRETIMELIMITL
  [6:4] DIGCLKRETIMELIMITH
  [2] DIGCLKRETIMERESETN
    0=operate; 1=reset
  [1] DIGCLKRETIMEDISRETIME
    0=enable_retime; 1=disable_retime
  [0] DIGCLKRETIMEENRETIME
    0=disable; 1=enable
0x160 DIGCLKRETIMESTATUS ro
  [1] DIGCLKRETIMERESETNLO
    0=lo; 1=hi
  [0] DIGCLKRETIMECLKSEL
    0=use_raw_clk; 1=use_retimed_clk
0x164 XORETIMECTRL
  [10:8] XORETIMELIMITL
  [6:4] XORETIMELIMITH
  [2] XORETIMERESETN
    0=operate; 1=reset
  [1] XORETIMEDISRETIME
    0=enable_retime; 1=disable_retime
  [0] XORETIMEENRETIME
    0=disable; 1=enable
0x168 XORETIMESTATUS ro
  [1] XORETIMERESETNLO
    0=lo; 1=hi
  [0] XORETIMECLKSEL
    0=use_raw_clk; 1=use_retimed_clk
0x16C XOSQBUFFILT
  [1:0] XOSQBUFFILT
    0=bypass; 1=filter_1; 2=filter_2; 3=filter_3
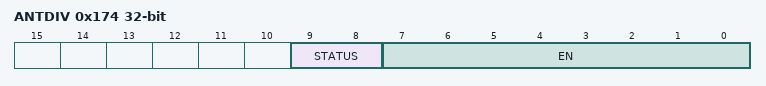
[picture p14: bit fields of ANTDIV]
0x174 ANTDIV
  [9:8] STATUS ro
    0=OFF (Both antenna disabled); 1=ANT1 (Antenna 1 enabled); 2=ANT2 (Antenna 2 enabled); 3=BOTH (Both antenna enabled)
  [7:0] EN
    0=OFF (All controls off); 1=PAENANT1 (Control pa_en_ant1); 2=LNAMIXEN1 (Control lnamix_en1); 4=LNAMIXRFPKDENRF1 (Control lnamix_rfpkd_en_rf1); 8=SYLODIVRLO12G4EN (Control sy_lodiv_rlo1_2g4_en); 16=PAENANT2 (Control pa_en_ant2); 32=LNAMIXEN2 (Control lnamix_en2); 64=LNAMIXRFPKDENRF2 (Control lnamix_rfpkd_en_rf2); 128=SYLODIVRLO22G4EN (Control sy_lodiv_rlo2_2g4_en); 255=ON (All controls on)
{0x3E0+4i} SCRATCH{i} (i=0..7)
